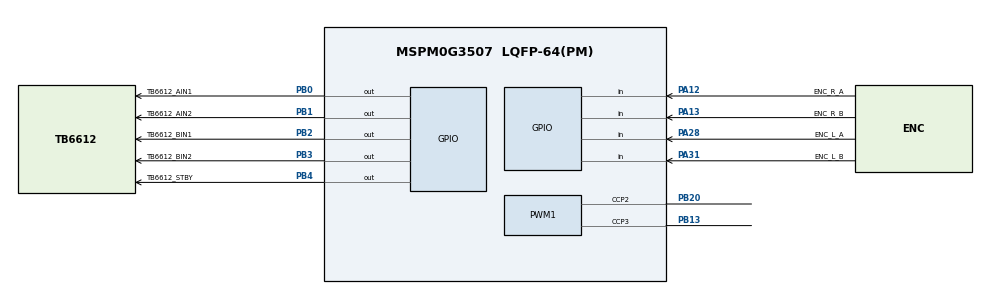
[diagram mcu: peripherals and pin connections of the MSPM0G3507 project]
/**
 * These arguments were used when this file was generated. They will be automatically applied on subsequent loads
 * via the GUI or CLI. Run CLI with '--help' for additional information on how to override these arguments.
 * @cliArgs --device "MSPM0G350X" --part "Default" --package "LQFP-64(PM)" --product "mspm0_sdk@2.11.00.07"
 * @v2CliArgs --device "MSPM0G3507" --package "LQFP-64(PM)" --product "mspm0_sdk@2.11.00.07"
 * @versions {"tool":"1.26.2+4477"}
 */

/**
 * Import the modules used in this configuration.
 */
const GPIO   = scripting.addModule("/ti/driverlib/GPIO", {}, false);
const GPIO1  = GPIO.addInstance();
const GPIO2  = GPIO.addInstance();
const PWM    = scripting.addModule("/ti/driverlib/PWM", {}, false);
const PWM1   = PWM.addInstance();
const SYSCTL = scripting.addModule("/ti/driverlib/SYSCTL");

/**
 * Write custom configuration values to the imported modules.
 */
GPIO1.$name                         = "MOTOR_CTRL";
GPIO1.associatedPins.create(5);
GPIO1.associatedPins[0].$name       = "TB6612_AIN1";
GPIO1.associatedPins[0].pin.$assign = "PB0";
GPIO1.associatedPins[1].$name       = "TB6612_AIN2";
GPIO1.associatedPins[1].pin.$assign = "PB1";
GPIO1.associatedPins[2].$name       = "TB6612_BIN1";
GPIO1.associatedPins[2].pin.$assign = "PB2";
GPIO1.associatedPins[3].$name       = "TB6612_BIN2";
GPIO1.associatedPins[3].pin.$assign = "PB3";
GPIO1.associatedPins[4].$name       = "TB6612_STBY";
GPIO1.associatedPins[4].pin.$assign = "PB4";

const Board = scripting.addModule("/ti/driverlib/Board", {}, false);

GPIO2.$name                              = "ENCODER";
GPIO2.associatedPins.create(4);
GPIO2.associatedPins[0].$name            = "ENC_L_A";
GPIO2.associatedPins[0].internalResistor = "PULL_UP";
GPIO2.associatedPins[0].direction        = "INPUT";
GPIO2.associatedPins[0].pin.$assign      = "PA28";
GPIO2.associatedPins[1].$name            = "ENC_L_B";
GPIO2.associatedPins[1].direction        = "INPUT";
GPIO2.associatedPins[1].pin.$assign      = "PA31";
GPIO2.associatedPins[2].$name            = "ENC_R_A";
GPIO2.associatedPins[2].direction        = "INPUT";
GPIO2.associatedPins[2].pin.$assign      = "PA12";
GPIO2.associatedPins[3].$name            = "ENC_R_B";
GPIO2.associatedPins[3].direction        = "INPUT";
GPIO2.associatedPins[3].pin.$assign      = "PA13";

PWM1.$name                      = "MOTOR_PWM";
PWM1.pwmMode                    = "EDGE_ALIGN_UP";
PWM1.timerCount                 = 1600;
PWM1.ccIndex                    = [2,3];
PWM1.peripheral.$assign         = "TIMA0";
PWM1.peripheral.ccp2Pin.$assign = "PB20";
PWM1.peripheral.ccp3Pin.$assign = "PB13";
PWM1.PWM_CHANNEL_2.$name        = "ti_driverlib_pwm_PWMTimerCC0";
PWM1.PWM_CHANNEL_3.$name        = "ti_driverlib_pwm_PWMTimerCC3";
PWM1.ccp2PinConfig.$name        = "ti_driverlib_gpio_GPIOPinGeneric2";
PWM1.ccp3PinConfig.$name        = "ti_driverlib_gpio_GPIOPinGeneric3";

SYSCTL.forceDefaultClkConfig = true;

/**
 * Pinmux solution for unlocked pins/peripherals. This ensures that minor changes to the automatic solver in a future
 * version of the tool will not impact the pinmux you originally saw.  These lines can be completely deleted in order to
 * re-solve from scratch.
 */
Board.peripheral.$suggestSolution          = "DEBUGSS";
Board.peripheral.swclkPin.$suggestSolution = "PA20";
Board.peripheral.swdioPin.$suggestSolution = "PA19";
SYSCTL.peripheral.$suggestSolution         = "SYSCTL";
